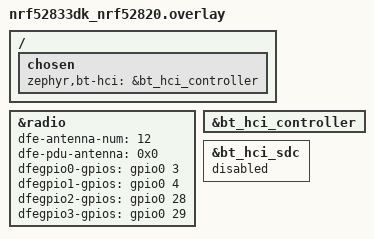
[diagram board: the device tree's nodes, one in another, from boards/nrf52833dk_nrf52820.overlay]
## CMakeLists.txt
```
#
# Copyright (c) 2022 Nordic Semiconductor ASA
#
# SPDX-License-Identifier: LicenseRef-Nordic-5-Clause
#

cmake_minimum_required(VERSION 3.20.0)

find_package(Zephyr REQUIRED HINTS $ENV{ZEPHYR_BASE})

project(direction_finding_peripheral)

# NORDIC SDK APP START
target_sources(app PRIVATE
  src/main.c
)
# NORDIC SDK APP END
```

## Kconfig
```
#
# Copyright (c) 2025 Nordic Semiconductor
#
# SPDX-License-Identifier: LicenseRef-Nordic-5-Clause
#

# RAM for this application for this board is too few to use
# the BT TX processor thread.
configdefault BT_TX_PROCESSOR_THREAD
	default n if BOARD_NRF52833DK_NRF52820

source "Kconfig.zephyr"
```

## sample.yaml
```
sample:
  name: Direction Finding Peripheral
  description: Sample application showing peripheral role of Direction Finding in
    connected mode
common:
  tags:
    - bluetooth
    - sysbuild
    - ci_samples_bluetooth
tests:
  sample.bluetooth.direction_finding_peripheral.aoa.sdc.nrf53_54lx:
    sysbuild: true
    platform_allow:
      - nrf5340dk/nrf5340/cpuapp
      - nrf54l15dk/nrf54l05/cpuapp
      - nrf54l15dk/nrf54l10/cpuapp
      - nrf54l15dk/nrf54l15/cpuapp
      - nrf54lm20dk/nrf54lm20a/cpuapp
      - nrf54lm20dk/nrf54lm20b/cpuapp
      - nrf54lv10dk/nrf54lv10a/cpuapp
      - nrf54lv10dk/nrf54lv10a/cpuapp/ns
      - nrf54lc10dk/nrf54lc10a/cpuapp
      - nrf54lc10dk/nrf54lc10a/cpuapp/ns
    integration_platforms:
      - nrf5340dk/nrf5340/cpuapp
      - nrf54l15dk/nrf54l15/cpuapp
    harness: console
    harness_config:
      type: multi_line
      ordered: true
      regex:
        - "Bluetooth initialized"
        - "Advertising successfully started"
    timeout: 15
  sample.bluetooth.direction_finding_peripheral.aoa.bt_ll_sw_split.nrf53:
    sysbuild: true
    build_only: true
    extra_args:
      - ipc_radio_OVERLAY_CONFIG="../../overlay-bt_ll_sw_split.conf"
      - ipc_radio_SNIPPET="bt-ll-sw-split"
    platform_allow:
      - nrf5340dk/nrf5340/cpuapp
    integration_platforms:
      - nrf5340dk/nrf5340/cpuapp
  sample.bluetooth.direction_finding_peripheral.all.bt_ll_sw_split.nrf53:
    sysbuild: true
    build_only: true
    extra_args:
      - ipc_radio_OVERLAY_CONFIG="../../overlay-aod.conf;../../overlay-bt_ll_sw_split.conf"
      - ipc_radio_SNIPPET="bt-ll-sw-split"
    platform_allow:
      - nrf5340dk/nrf5340/cpuapp
    integration_platforms:
      - nrf5340dk/nrf5340/cpuapp
```

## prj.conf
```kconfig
#
# Copyright (c) 2022 Nordic Semiconductor ASA
#
# SPDX-License-Identifier: LicenseRef-Nordic-5-Clause
#

CONFIG_BT=y
CONFIG_LOG=y
CONFIG_BT_DEVICE_NAME="DF Conn App"
CONFIG_BT_SMP=y

CONFIG_BT_PERIPHERAL=y
CONFIG_BT_DEVICE_APPEARANCE=833

# Enable Direction Finding Feature RX in connected mode
CONFIG_BT_DF=y
CONFIG_BT_DF_CONNECTION_CTE_TX=y
CONFIG_BT_DF_CONNECTION_CTE_RSP=y

# Disable AoD Feature (antenna switching) in Tx mode in Host
CONFIG_BT_DF_CTE_TX_AOD=n

# Don't use BT TX processor thread due to limited RAM.
CONFIG_BT_TX_PROCESSOR_THREAD=n
```

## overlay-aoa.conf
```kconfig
#
# Copyright (c) 2022 Nordic Semiconductor ASA
#
# SPDX-License-Identifier: LicenseRef-Nordic-5-Clause
#

# Disable AoD Feature (antenna switching) in Tx mode in Controller and Host
CONFIG_BT_CTLR_DF_ANT_SWITCH_TX=n
CONFIG_BT_DF_CTE_TX_AOD=n
```

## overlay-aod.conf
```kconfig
#
# Copyright (c) 2025 Nordic Semiconductor ASA
#
# SPDX-License-Identifier: LicenseRef-Nordic-5-Clause
#

# Enable AoD Feature (antenna switching) in Tx mode in Controller and Host
CONFIG_BT_CTLR_DF_ANT_SWITCH_TX=y
CONFIG_BT_DF_CTE_TX_AOD=n
```

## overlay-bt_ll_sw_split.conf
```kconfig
#
# Copyright (c) 2022 Nordic Semiconductor ASA
#
# SPDX-License-Identifier: LicenseRef-Nordic-5-Clause
#

# Enable Direction Finding Feature
CONFIG_BT_CTLR_DF=y

CONFIG_BT_CTLR_DF_CTE_TX=y
CONFIG_BT_CTLR_DF_CONN_CTE_TX=y
CONFIG_BT_CTLR_DF_ANT_SWITCH_TX=y
CONFIG_BT_CTLR_DF_CONN_CTE_RSP=y

# Ensure that there are enough control procedure contexts to queue and execute all procedures
CONFIG_BT_CTLR_ADVANCED_FEATURES=y
CONFIG_BT_CTLR_LLCP_LOCAL_PROC_CTX_BUF_NUM=6
```

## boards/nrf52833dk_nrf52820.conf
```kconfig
#
# Copyright (c) 2022 Nordic Semiconductor ASA
#
# SPDX-License-Identifier: LicenseRef-Nordic-5-Clause
#

# Enable Direction Finding Feature
CONFIG_BT_CTLR_DF=y

CONFIG_BT_CTLR_DF_CTE_TX=y
CONFIG_BT_CTLR_DF_CONN_CTE_TX=y
CONFIG_BT_CTLR_DF_CONN_CTE_RSP=y

# Disable AoD Feature (antenna switching) in Tx mode in Controller
CONFIG_BT_CTLR_DF_ANT_SWITCH_TX=n

# Reduce RAM usage on this constrained board
CONFIG_DF_PERIPHERAL_DISABLE_BT_TX_THREAD=y
```

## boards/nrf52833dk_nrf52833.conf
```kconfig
#
# Copyright (c) 2022 Nordic Semiconductor ASA
#
# SPDX-License-Identifier: LicenseRef-Nordic-5-Clause
#

# Enable Direction Finding Feature including AoA and AoD
CONFIG_BT_CTLR_DF=y

CONFIG_BT_CTLR_DF_CTE_TX=y
CONFIG_BT_CTLR_DF_CONN_CTE_TX=y
CONFIG_BT_CTLR_DF_ANT_SWITCH_TX=y
CONFIG_BT_CTLR_DF_CONN_CTE_RSP=y
```

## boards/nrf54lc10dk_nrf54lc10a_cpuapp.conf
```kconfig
#
# Copyright (c) 2026 Nordic Semiconductor ASA
#
# SPDX-License-Identifier: LicenseRef-Nordic-5-Clause
#

# Enable Direction Finding Feature
CONFIG_BT_CTLR_DF=y

CONFIG_BT_CTLR_DF_CTE_TX=y
CONFIG_BT_CTLR_DF_CONN_CTE_TX=y
CONFIG_BT_CTLR_DF_CONN_CTE_RSP=y

# Disable AoD Feature (antenna switching) in Tx mode in Controller
CONFIG_BT_CTLR_DF_ANT_SWITCH_TX=n
```

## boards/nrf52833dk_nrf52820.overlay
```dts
/*
 * Copyright (c) 2022 Nordic Semiconductor ASA
 *
 * SPDX-License-Identifier: LicenseRef-Nordic-5-Clause
 */

&radio {
	status = "okay";
	/* This is the number of antennas that are available on the antenna matrix
	 * designed by Nordic Semiconductor. For more information see README.rst.
	 */
	dfe-antenna-num = <12>;
	/* This is a setting that enables antenna 0 (in antenna matrix designed
	 * by Nordic Semiconductor) for Rx PDU. For more information see README.rst.
	 */
	dfe-pdu-antenna = <0x0>;

	/* These are GPIO pin numbers that are provided to
	 * Radio peripheral. The pins will be acquired by Radio to
	 * drive antenna switching when AoA is enabled.
	 * Pin numbers are selected to drive switches on antenna matrix
	 * desinged by Nordic Semiconductor. For more information see README.rst.
	 */
	dfegpio0-gpios = <&gpio0 3 0>;
	dfegpio1-gpios = <&gpio0 4 0>;
	dfegpio2-gpios = <&gpio0 28 0>;
	dfegpio3-gpios = <&gpio0 29 0>;
};

&bt_hci_controller {
	status = "okay";
};

&bt_hci_sdc {
	status = "disabled";
};

/ {
	chosen {
		zephyr,bt-hci = &bt_hci_controller;
	};
};
```

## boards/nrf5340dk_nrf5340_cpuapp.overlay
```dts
/*
 * Copyright (c) 2022 Nordic Semiconductor ASA
 *
 * SPDX-License-Identifier: LicenseRef-Nordic-5-Clause
 */

/* Enable pin forwarding to the network core. The selected pins will be used by
 * the Radio Direction Finding Extension for antenna switching purposes.
 *
 * Note: Pay attention to assigning the same GPIO pins as those provided in
 * the network core DTS overlay.
 */
&gpio_fwd {
	dfe-gpio-if {
		gpios = <&gpio0 4 0>,
			<&gpio0 5 0>,
			<&gpio0 6 0>,
			<&gpio0 7 0>;
	};
};
```

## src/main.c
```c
/*
 * Copyright (c) 2022 Nordic Semiconductor ASA
 *
 * SPDX-License-Identifier: LicenseRef-Nordic-5-Clause
 */

#include <zephyr/types.h>
#include <errno.h>
#include <zephyr/sys/printk.h>
#include <zephyr/sys/byteorder.h>
#include <zephyr/kernel.h>

#include <zephyr/bluetooth/bluetooth.h>
#include <zephyr/bluetooth/hci.h>
#include <zephyr/bluetooth/conn.h>
#include <zephyr/bluetooth/direction.h>

#define DF_FEAT_ENABLED BIT64(BT_LE_FEAT_BIT_CONN_CTE_RESP)

static const struct bt_data ad[] = {
	BT_DATA_BYTES(BT_DATA_FLAGS, (BT_LE_AD_GENERAL | BT_LE_AD_NO_BREDR)),
	BT_DATA_BYTES(BT_DATA_LE_SUPPORTED_FEATURES, BT_LE_SUPP_FEAT_24_ENCODE(DF_FEAT_ENABLED)),
	BT_DATA(BT_DATA_NAME_COMPLETE, CONFIG_BT_DEVICE_NAME, sizeof(CONFIG_BT_DEVICE_NAME) - 1),
};

/* Latency set to zero, to enforce PDU exchange every connection event */
#define CONN_LATENCY 0U
/* Interval used to run CTE request procedure periodically.
 * Value is a number of connection events.
 */
#define CTE_REQ_INTERVAL (CONN_LATENCY + 10U)
/* Length of CTE in unit of 8 us */
#define CTE_LEN (0x14U)

#if defined(CONFIG_BT_DF_CTE_TX_AOD)
/* Example sequence of antenna switch patterns for antenna matrix designed by
 * Nordic. For more information about antenna switch patterns see README.rst.
 */
static uint8_t ant_patterns[] = {0x2, 0x0, 0x5, 0x6, 0x1, 0x4, 0xC, 0x9, 0xE,
				 0xD, 0x8, 0xA};
#endif /* CONFIG_BT_DF_CTE_TX_AOD */

static void enable_cte_response(struct bt_conn *conn)
{
	int err;

	const struct bt_df_conn_cte_tx_param cte_tx_params = {
#if defined(CONFIG_BT_DF_CTE_TX_AOD)
		.cte_types = BT_DF_CTE_TYPE_ALL,
		.num_ant_ids = ARRAY_SIZE(ant_patterns),
		.ant_ids = ant_patterns,
#else
		.cte_types = BT_DF_CTE_TYPE_AOA,
#endif /* CONFIG_BT_DF_CTE_TX_AOD */
	};

	printk("Set CTE transmission params...");
	err = bt_df_set_conn_cte_tx_param(conn, &cte_tx_params);
	if (err) {
		printk("failed (err %d)\n", err);
		return;
	}
	printk("success.\n");

	printk("Set CTE response enable...");
	err = bt_df_conn_cte_rsp_enable(conn);
	if (err) {
		printk("failed (err %d).\n", err);
		return;
	}
	printk("success.\n");
}

static void connected(struct bt_conn *conn, uint8_t err)
{
	if (err) {
		printk("Connection failed, err 0x%02x %s\n", err, bt_hci_err_to_str(err));
	} else {
		printk("Connected\n");

		enable_cte_response(conn);
	}
}

static void disconnected(struct bt_conn *conn, uint8_t reason)
{
	printk("Disconnected, reason 0x%02x %s\n", reason, bt_hci_err_to_str(reason));
}

BT_CONN_CB_DEFINE(conn_callbacks) = {
	.connected = connected,
	.disconnected = disconnected,
};

static void bt_ready(void)
{
	int err;

	printk("Bluetooth initialized\n");

	err = bt_le_adv_start(BT_LE_ADV_CONN_FAST_2, ad, ARRAY_SIZE(ad), NULL, 0);
	if (err) {
		printk("Advertising failed to start (err %d)\n", err);
		return;
	}

	printk("Advertising successfully started\n");
}

int main(void)
{
	int err;

	err = bt_enable(NULL);
	if (err) {
		printk("Bluetooth init failed (err %d)\n", err);
		return 0;
	}

	bt_ready();

	return 0;
}
```
